VERSION "HIPBNYYYYYYYYYYYYYYYYYYYYYYYYYYYYYYYYYYYYY/4/%%%/4/'%**4YYY///"

NS_ :

BS_:

BU_:

BO_ 123 Message: 8 Vector__XXX
 SG_ signalWithValues : 0|8@1+ (1,0) [0|255] "" Vector__XXX
 SG_ signalWithUnitAndComment : 8|16@1+ (1,0) [0|65535] "deg C" Vector__XXX

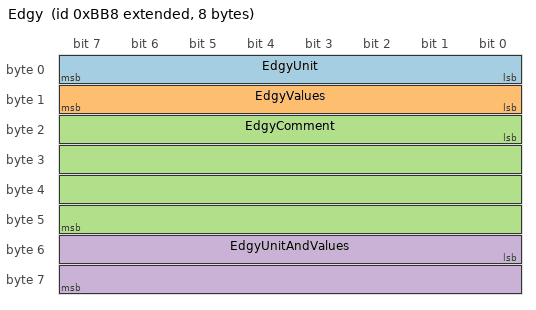
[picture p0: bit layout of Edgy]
BO_ 2147486648 Edgy: 8 Vector__XXX
 SG_ EdgyUnit : 0|8@1- (1,0) [0|0] "\" ' , ° . ' \" ; :" Vector__XXX
 SG_ EdgyValues : 15|8@0+ (1,0) [0|0] "" Vector__XXX
 SG_ EdgyComment : 16|32@1+ (1,0) [0|0] "" Vector__XXX
 SG_ EdgyUnitAndValues : 48|16@1+ (1,0) [0|0] "impossible" Vector__XXX

BO_ 2147486647 Multiplexed: 8 Vector__XXX
 SG_ Multiplexor M : 0|4@1+ (1,0) [0|0] "" Vector__XXX
 SG_ soc m0 : 8|8@1+ (0.5,0) [0|100] "%" Vector__XXX
 SG_ speed m1 : 8|8@1+ (1,-50) [-50|150] "km/h" Vector__XXX

BO_ 2147486646 EdgySignedStuff: 8 Vector__XXX
 SG_ shouldConvert : 0|1@1- (1,0) [0|0] "I should be unsigned because signed integers dont make sense" Vector__XXX
 SG_ shouldNotConvert : 1|2@1- (1,0) [0|0] "I should remain signed" Vector__XXX

CM_ BO_ 123 "Message comment";
CM_ SG_ 123 signalWithUnitAndComment "Signal comment";
CM_ BO_ 2147486648 ": ; > , . < ' \" [ ] { } \ | \\ -- # ' \"";
VAL_ 123 signalWithValues 0 "Off" 1 "On" 255 "Ignore" 254 "This device is on fire" ;
VAL_ 2147486648 EdgyValues 0 "Lekker laag" 255 "Edgy: ' \" ° , . \" '" ;
